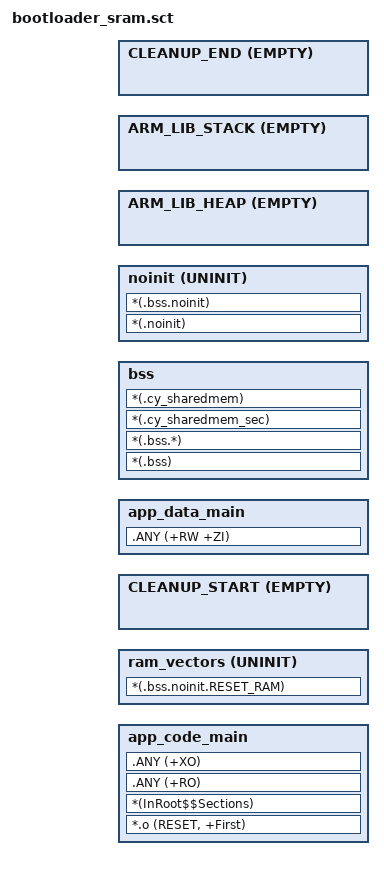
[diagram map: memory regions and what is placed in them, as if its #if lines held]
#! armclang -E --target=arm-arm-none-eabi -mcpu=cortex-m33 -xc
; command above MUST be in first line (no comment above!)
/***************************************************************************//**
* \file bootloader_sram.sct
* \version 1.0.0
*
* scatter file for the armclang C compiler.
*
* The main purpose of this file is to describe how the sections in the
* input files should be mapped into the output file, and to control the memory
* layout of the output file.
*
*
* \note The linker files included with the PDL template projects must be
* generic and handle all common use cases. Your project may not use every
* section defined in the linker files. In that case you may see the warnings
* during the build process: L6314W (no section matches pattern) and/or L6329W
* (pattern only matches removed unused sections). In your project, you can
* suppress the warning by passing the "--diag_suppress=L6314W,L6329W" option to
* the linker, simply comment out or remove the relevant code in the linker
* file.
*
********************************************************************************
* \copyright
* Copyright (c) (2020-2025), Cypress Semiconductor Corporation (an Infineon company) or
* an affiliate of Cypress Semiconductor Corporation.
* SPDX-License-Identifier: Apache-2.0
*
* Licensed under the Apache License, Version 2.0 (the "License");
* you may not use this file except in compliance with the License.
* You may obtain a copy of the License at
*
*     http://www.apache.org/licenses/LICENSE-2.0
*
* Unless required by applicable law or agreed to in writing, software
* distributed under the License is distributed on an "AS IS" BASIS,
* WITHOUT WARRANTIES OR CONDITIONS OF ANY KIND, either express or implied.
* See the License for the specific language governing permissions and
* limitations under the License.
*******************************************************************************/

/* Include the device memory definitions generated by the Device Configurator */
#include "../../config/GeneratedSource/cymem_armlink_CM33_0_S.sct"

/* Define the stack size for the application */
/* To set stack size in application add makefile ldflags: --predefine="-DAPP_MSP_STACK_SIZE=<CUSTOM_VALUE>" */
#ifdef APP_MSP_STACK_SIZE
#define __STACK_SIZE    APP_MSP_STACK_SIZE
#else
#define __STACK_SIZE    0x00002000
#endif

/* User Stack & Heap boundary definition */
/* Place the top of the stack at the end of the m33s_data_S */
#define __STACK_TOP    (CYMEM_CM33_0_S_m33s_data_S_START + CYMEM_CM33_0_S_m33s_data_SIZE)
/* Position the beginning of the heap right after the noinit ER, ensuring an 8-byte alignment */
#define __HEAP_BASE    AlignExpr(ImageLimit(noinit), 8)
/* The heap extends to the stack */
#define __HEAP_SIZE    (__STACK_TOP - __STACK_SIZE - __HEAP_BASE)

/* Device definitions */
#define VECTORS_ALIGNMENT 0x400

/* The size of the MCU boot header area at the start of main code region */
#define MCUBOOT_HEADER_SIZE  0x400

/* The size of the signature trail area at the end of main code region */
#define SIGNATURE_TRAIL_SIZE 0x400


/* SRAM execution */
LR_SRAM_CODE (CYMEM_CM33_0_S_bootloader_sram_code_S_START + MCUBOOT_HEADER_SIZE) (CYMEM_CM33_0_S_bootloader_sram_code_SIZE - MCUBOOT_HEADER_SIZE - SIGNATURE_TRAIL_SIZE)
{
  /* The execution region is now in SRAM code area instead of flash */
  app_code_main (CYMEM_CM33_0_S_bootloader_sram_code_S_START + MCUBOOT_HEADER_SIZE) ALIGN VECTORS_ALIGNMENT (CYMEM_CM33_0_S_bootloader_sram_code_SIZE - MCUBOOT_HEADER_SIZE - SIGNATURE_TRAIL_SIZE)
  {
    *.o (RESET, +First)
    *(InRoot$$Sections)
    .ANY (+RO)
    .ANY (+XO)
  }

  /* A region for the vector table */
  ram_vectors CYMEM_CM33_0_S_m33s_data_S_START ALIGN VECTORS_ALIGNMENT UNINIT
  {
    *(.bss.noinit.RESET_RAM)
  }

  /* This empty, zero long execution region is here to mark the start address of cleanup region */
  CLEANUP_START AlignExpr(ImageLimit(ram_vectors), 4) ALIGN 4 EMPTY 0x0 {}

  /* The execution region for initialized data memory */
  app_data_main AlignExpr(ImageLimit(ram_vectors), 4) ALIGN 4
  {
    .ANY (+RW +ZI)
  }
  /* A section for non-initialized data memory */
  bss AlignExpr(ImageLimit(app_data_main), 8) ALIGN 8 
  {
    *(.bss)
    *(.bss.*)
    *(.cy_sharedmem_sec)
    *(.cy_sharedmem)
  }

  /* A region for variables that should not be initialized during the device startup */
  noinit AlignExpr(ImageLimit(bss), 4) ALIGN 4 UNINIT 
  {
    *(.noinit)
    *(.bss.noinit)
  }
}

/* SRAM Data Region */
LR_SRAM CYMEM_CM33_0_S_m33s_data_S_START CYMEM_CM33_0_S_m33s_data_SIZE
{

  /* A region for the heap memory */
  ARM_LIB_HEAP __HEAP_BASE EMPTY __HEAP_SIZE
  {
  }

  /* A region for stack */
  ARM_LIB_STACK __STACK_TOP EMPTY -__STACK_SIZE
  {
  }

  /* This empty, zero long execution region is here to mark the end address of cleanup region */
  CLEANUP_END __STACK_TOP EMPTY 0x0 {}
}
